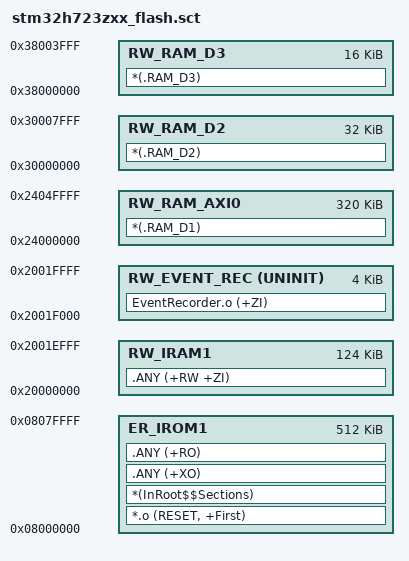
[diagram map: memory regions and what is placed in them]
; *********************************************************************************
; *** Scatter-Loading Description File - STM32H723 分散加载描述文件             ***
; ***                                                                           ***
; *** RAM 段约定(与 FML/includes.h 的 __RAM_Dx_ 宏一一对应):                    ***
; ***   .RAM_D1 -> AXI SRAM      0x24000000(总窗口 320KB = SRAM1 128KB          ***
; ***                                @0x24000000 + SRAM2 192KB @0x24020000,     ***
; ***                                可被 D-Cache 缓存 -> 计算数据)             ***
; ***   .RAM_D2 -> D2 SRAM1+SRAM2 0x30000000(共 32KB,DMA1/2 可达 -> DMA 缓冲)  ***
; ***   .RAM_D3 -> SRAM4         0x38000000(16KB,仅 BDMA 可达)                  ***
; ***                                                                           ***
; *** DTCM 0x20000000(128KB)分区:                                              ***
; ***   0x20000000 ~ 0x2001EFFF(124KB):所有普通 RW/ZI(全局/堆/栈)              ***
; ***   0x2001F000 ~ 0x2001FFFF(4KB):EventRecorder 记录缓冲(当前未启用,        ***
; ***        会报 L6314W: No section matches pattern EventRecorder.o(+ZI),正常) ***
; ***                                                                           ***
; *** ITCM 0x00000000(64KB):                                                   ***
; ***   0x0 ~ 0x3FF 由 main() 在运行时拷入向量表并设置 SCB->VTOR = 0x00000000, ***
; ***   链接器不要往 ITCM 放任何内容(数据会被向量拷贝静默覆盖)!               ***
; *********************************************************************************

LR_IROM1 0x08000000 0x00080000  {  ; Load Region:整个镜像在 Flash,最大 512KB
  ER_IROM1 0x08000000 0x00080000  {  ; 执行地址 = 加载地址,代码就地执行
    *.o (RESET, +First)              ; 向量表(启动汇编 AREA RESET)放 Flash 开头
    *(InRoot$$Sections)              ; C 库启动 / 散列加载代码
    .ANY (+XO)
    .ANY (+RO)
  }

  ; ---------------------------------------------------------------------------
  ; ITCM 使用说明:
  ;   1) 向量表:main() 里 memcpy 到 0x00000000 并设 VTOR,故 0x0~0x3FF
  ;      绝不能有链接内容,否则会被该 memcpy 静默覆盖;
  ;   2) 需要"零等待执行"的关键函数/ISR 时:在函数上标注
  ;      __attribute__((section(".ITCM"))),并取消下面区域注释;
  ;      散列加载会在 main() 之前自动把代码从 Flash 拷入 ITCM 并就地执行。
  ; ---------------------------------------------------------------------------
  ; ER_ITCM_CODE 0x00000400 0x0000FC00  {
  ;   *(.ITCM)
  ; }

  ; ---------------------------------------------------------------------------
  ; 分散加载问答:DTCM 只是"默认家",不是只能放这。
  ; 所有普通 RW/ZI 都进 DTCM,只是因为 .ANY (+RW +ZI) 只在 RW_IRAM1 声明。
  ; 想手动把"普通"数据分流到别的 RAM,任选其一:
  ;   a) 变量级:定义时标 __RAM_D1_ / __RAM_D2_ / __RAM_D3_(见 FML/includes.h);
  ;   b) 文件级:把整个 .o 挪走,例如把 FreeRTOS 堆放到 AXI SRAM:
  ;        RW_RAM_AXI0 区域里追加: heap_4.o (+RW +ZI)
  ;        (ucHeap 是纯 CPU 内存,放 AXI 没任何问题,还能给 DTCM 腾地方);
  ;   c) 段级:自定义 section,做法同上面的 .ITCM。
  ; 有多个 .ANY (+RW +ZI) 区域时,链接器按 scatter 里出现的先后顺序优先分配。
  ; ---------------------------------------------------------------------------

  RW_IRAM1 0x20000000 0x0001F000  {  ; DTCM:0x20000000 ~ 0x2001EFFF(124KB)
    .ANY (+RW +ZI)                   ; 全部普通 RW/ZI:全局变量、FreeRTOS 堆、栈
  }

  RW_EVENT_REC 0x2001F000 UNINIT 0x00001000  {  ; DTCM 顶部 4KB:EventRecorder
    EventRecorder.o (+ZI)                        ; 记录缓冲(每条约 16B,
  }                                              ; 4KB 最多容纳 256 条)
                                                 ; (UNINIT:启动不清零)

  RW_RAM_AXI0 0x24000000 0x00050000  {  ; AXI SRAM 总窗口 320KB(SRAM1+SRAM2),
    *(.RAM_D1)                           ; 可被 D-Cache 缓存(MPU Region0/1 覆盖:
  }                                      ; 256KB@0x24000000 + 64KB@0x24040000)

  RW_RAM_D2 0x30000000 0x00008000  {  ; D2 SRAM1+SRAM2 共 32KB(DMA1/2 可达)
    *(.RAM_D2)                         ; 外设 DMA 收发缓冲;MPU Region2 已配成
  }                                    ; non-cacheable,模块内手动 cache 调用
                                       ; 可保留(无害)或逐步删除
  RW_RAM_D3 0x38000000 0x00004000  {  ; SRAM4 16KB(仅 BDMA 可达)
    *(.RAM_D3)
  }
}
